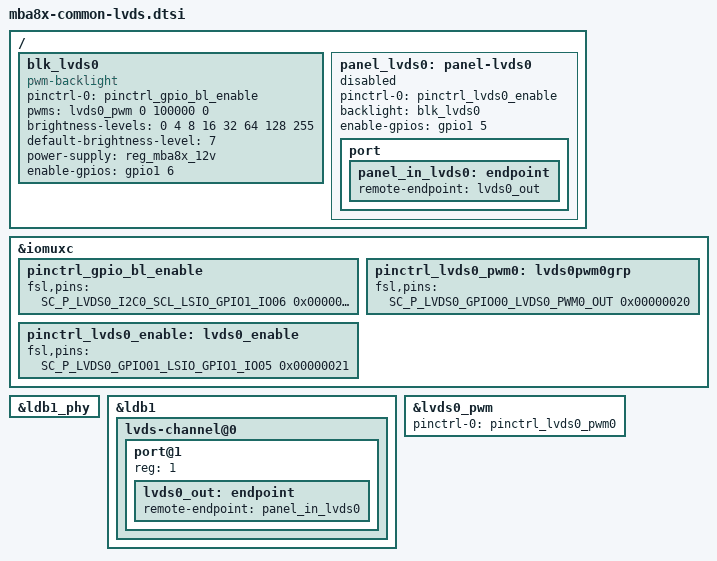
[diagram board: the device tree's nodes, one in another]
/*
 * Copyright 2018-2019 TQ Systems GmbH
 *
 * This program is free software; you can redistribute it and/or
 * modify it under the terms of the GNU General Public License
 * as published by the Free Software Foundation; either version 2
 * of the License, or (at your option) any later version.
 *
 * This program is distributed in the hope that it will be useful,
 * but WITHOUT ANY WARRANTY; without even the implied warranty of
 * MERCHANTABILITY or FITNESS FOR A PARTICULAR PURPOSE.  See the
 * GNU General Public License for more details.
 */

#include "mba8x-common-drm.dtsi"

/ {
	blk_lvds0: blk_lvds0 {

		compatible = "pwm-backlight";
		pinctrl-names = "default";
		pinctrl-0 = <&pinctrl_gpio_bl_enable>;
		pwms = <&lvds0_pwm 0 100000 0>;
		brightness-levels = <0 4 8 16 32 64 128 255>;
		default-brightness-level = <7>;
		power-supply = <&reg_mba8x_12v>;
		enable-gpios = <&gpio1 6 GPIO_ACTIVE_HIGH>;
		status = "okay";
	};

	panel_lvds0: panel-lvds0 {
		pinctrl-names = "default";
		pinctrl-0 = <&pinctrl_lvds0_enable>;
		backlight = <&blk_lvds0>;
		enable-gpios = <&gpio1 5 GPIO_ACTIVE_HIGH>;
		status = "disabled";

		port {
			panel_in_lvds0: endpoint {
				remote-endpoint = <&lvds0_out>;
			};
		};
	};
};

&iomuxc {

	pinctrl_gpio_bl_enable: pinctrl_gpio_bl_enable {
		fsl,pins = <
			SC_P_LVDS0_I2C0_SCL_LSIO_GPIO1_IO06	0x00000021
		>;
	};

	pinctrl_lvds0_enable: lvds0_enable {
		fsl,pins = <
			SC_P_LVDS0_GPIO01_LSIO_GPIO1_IO05	0x00000021
		>;
	};

	pinctrl_lvds0_pwm0: lvds0pwm0grp {
		fsl,pins = <
			SC_P_LVDS0_GPIO00_LVDS0_PWM0_OUT	0x00000020
		>;
	};

};

&ldb1_phy {
	status = "okay";
};

&ldb1 {
	status = "okay";

	lvds-channel@0 {
		status = "okay";

		port@1 {
			reg = <1>;

			lvds0_out: endpoint {
				remote-endpoint = <&panel_in_lvds0>;
			};
		};
	};
};

&lvds0_pwm {
	pinctrl-names = "default";
	pinctrl-0 = <&pinctrl_lvds0_pwm0>;
	status = "okay";
};
